AUTOSAR XML (schema 00050)
standard types defined: Boolean, Float
package /ARRoot
  sensor actuator sw component type ABSModulatorActuatorType
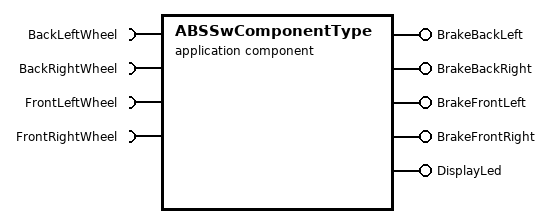
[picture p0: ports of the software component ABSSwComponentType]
  application sw component type ABSSwComponentType
    require port BackLeftWheel
    require port BackRightWheel
    5 x provide port:
      BrakeBackLeft
      BrakeBackRight
      BrakeFrontLeft
      BrakeFrontRight
      DisplayLed
    require port FrontLeftWheel
    require port FrontRightWheel
    behavior AbsIB
      9 x runnable:
        BackLeftWheelRunnable: variable-access=accessed-variable=/ARRoot/WheelSpeedSRIF/
        BackRightWheelRunnable: variable-access=accessed-variable=/ARRoot/WheelSpeedSRIF/
        BrakeBackLeftRunnable: asynchronous-server-call-point=Brake.
        BrakeBackRightRunnable: asynchronous-server-call-point=Brake.
        BrakeFrontLeftRunnable: asynchronous-server-call-point=Brake.
        BrakeFrontRightRunnable: asynchronous-server-call-point=FrontRightWheel.
        DisplayLedRunnable: variable-access=accessed-variable=/ARRoot/DisplayLedSRIF/
        FrontLeftWheelRunnable: variable-access=accessed-variable=/ARRoot/WheelSpeedSRIF/
        FrontRightWheelRunnable: variable-access=accessed-variable=/ARRoot/WheelSpeedSRIF/
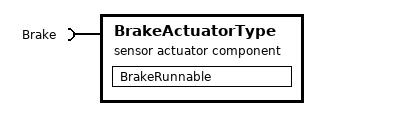
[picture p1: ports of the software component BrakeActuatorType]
  sensor actuator sw component type BrakeActuatorType
    require port Brake
    behavior BrakeIB
      runnable BrakeRunnable: external-triggering-point=BrakeBackLeft.TriggerForBrake
  client server interface BrakeCSIF
  sender receiver interface DisplayLedSRIF: data-elements=variable-data-prototype=type=Boolean
  trigger interface ExternalTriggerForBrake
    trigger TriggerForBrake
  impl type Integer
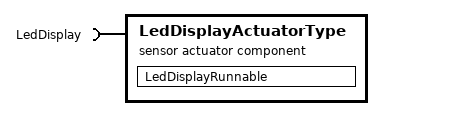
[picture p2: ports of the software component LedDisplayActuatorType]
  sensor actuator sw component type LedDisplayActuatorType
    require port LedDisplay
    behavior LedDisplayIB
      runnable LedDisplayRunnable
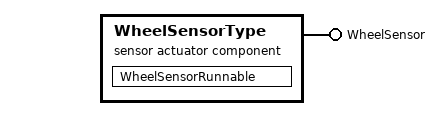
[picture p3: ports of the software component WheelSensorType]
  sensor actuator sw component type WheelSensorType
    provide port WheelSensor
    behavior WheelSensorIB
      runnable WheelSensorRunnable
  sender receiver interface WheelSpeedSRIF: data-elements=variable-data-prototype=type=Integer
